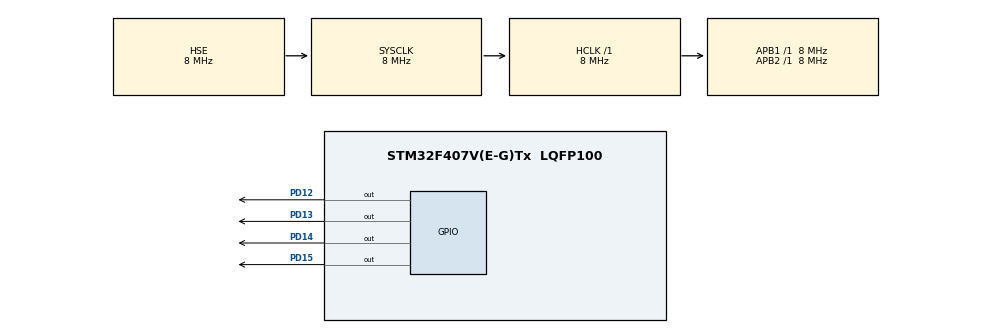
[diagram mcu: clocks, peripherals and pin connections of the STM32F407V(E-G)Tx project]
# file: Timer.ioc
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Mcu.Family=STM32F4
Mcu.Name=STM32F407V(E-G)Tx
Mcu.Package=LQFP100
NVIC.PriorityGroup=NVIC_PRIORITYGROUP_0
PA13.Mode=Serial_Wire
PA13.Signal=SYS_JTMS-SWDIO
PA14.Mode=Serial_Wire
PA14.Signal=SYS_JTCK-SWCLK
PD12.GPIO_PuPd=GPIO_PULLDOWN
PD12.Signal=GPIO_Output
PD13.GPIO_PuPd=GPIO_PULLDOWN
PD13.Signal=GPIO_Output
PD14.GPIO_PuPd=GPIO_PULLDOWN
PD14.Signal=GPIO_Output
PD15.GPIO_PuPd=GPIO_PULLDOWN
PD15.Signal=GPIO_Output
PH0-OSC_IN.Mode=HSE-External-Oscillator
PH0-OSC_IN.Signal=RCC_OSC_IN
PH1-OSC_OUT.Mode=HSE-External-Oscillator
PH1-OSC_OUT.Signal=RCC_OSC_OUT
ProjectManager.HeapSize=0x200
ProjectManager.StackSize=0x400
ProjectManager.TargetToolchain=STM32CubeIDE
RCC.48MHZClocksFreq_Value=13714285.714285715
RCC.AHBFreq_Value=8000000
RCC.APB1Freq_Value=8000000
RCC.APB1TimFreq_Value=8000000
RCC.APB2Freq_Value=8000000
RCC.APB2TimFreq_Value=8000000
RCC.CortexFreq_Value=8000000
RCC.HCLKFreq_Value=8000000
RCC.HSE_VALUE=8000000
RCC.HSI_VALUE=16000000
RCC.LSE_VALUE=32768
RCC.PLLQ=7
RCC.PLLSourceVirtual=RCC_PLLSOURCE_HSE
RCC.SYSCLKFreq_VALUE=8000000
RCC.SYSCLKSource=RCC_SYSCLKSOURCE_HSE
RCC.VCOOutputFreq_Value=96000000
TIM1.Period=1999
TIM1.Prescaler=7999
VP_TIM1_VS_ClockSourceINT.Mode=Internal
board=STM32F407G-DISC1

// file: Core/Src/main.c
/* USER CODE BEGIN Header */
/**
  ******************************************************************************
  * @file           : main.c
  * @brief          : Main program body
  ******************************************************************************
  * @attention
  *
  * Copyright (c) 2023 STMicroelectronics.
  * All rights reserved.
  *
  * This software is licensed under terms that can be found in the LICENSE file
  * in the root directory of this software component.
  * If no LICENSE file comes with this software, it is provided AS-IS.
  *
  ******************************************************************************
  */
/* USER CODE END Header */
#include "main.h"

TIM_HandleTypeDef htim1;

void SystemClock_Config(void);
static void MX_GPIO_Init(void);
static void MX_TIM1_Init(void);
/* USER CODE BEGIN PFP */
int state = 0;
/* USER CODE END PFP */

/* USER CODE BEGIN 0 */
HAL_TIM_PeriodElapsedCallback(TIM_HandleTypeDef *htim)
{
  state++ ;
  state = state % 2	;
  if(state == 0){
  HAL_GPIO_TogglePin(GPIOD, GPIO_PIN_12);
  HAL_GPIO_TogglePin(GPIOD, GPIO_PIN_13);
  HAL_GPIO_TogglePin(GPIOD, GPIO_PIN_14);
  HAL_GPIO_TogglePin(GPIOD, GPIO_PIN_15);
  }

}
/* USER CODE END 0 */

int main(void)
{

  /* MCU Configuration--------------------------------------------------------*/

  /* Reset of all peripherals, Initializes the Flash interface and the Systick. */
  HAL_Init();

  /* Configure the system clock */
  SystemClock_Config();

  /* Initialize all configured peripherals */
  MX_GPIO_Init();
  MX_TIM1_Init();
  /* USER CODE BEGIN 2 */
  HAL_TIM_Base_Start(&htim1);
  /* USER CODE END 2 */

  /* Infinite loop */
  while (1)
  {

    /* USER CODE BEGIN 3 */
	  if (__HAL_TIM_GET_FLAG(&htim1, TIM_FLAG_UPDATE)) // Timer tasmasi kontrolu
	     {
	       __HAL_TIM_CLEAR_FLAG(&htim1, TIM_FLAG_UPDATE); // Tasma bayragini temizle
	       // Timer taşması durumunda yapılacak işlemler
	       // Ornegin, bir LED'i yakabilirsiniz:
	       HAL_GPIO_TogglePin(GPIOD, GPIO_PIN_13);
	     }
  }
  /* USER CODE END 3 */
}

void SystemClock_Config(void)
{
  RCC_OscInitTypeDef RCC_OscInitStruct = {0};
  RCC_ClkInitTypeDef RCC_ClkInitStruct = {0};

  /** Configure the main internal regulator output voltage
  */
  __HAL_RCC_PWR_CLK_ENABLE();
  __HAL_PWR_VOLTAGESCALING_CONFIG(PWR_REGULATOR_VOLTAGE_SCALE1);

  /** Initializes the RCC Oscillators according to the specified parameters
  * in the RCC_OscInitTypeDef structure.
  */
  RCC_OscInitStruct.OscillatorType = RCC_OSCILLATORTYPE_HSE;
  RCC_OscInitStruct.HSEState = RCC_HSE_ON;
  RCC_OscInitStruct.PLL.PLLState = RCC_PLL_NONE;
  if (HAL_RCC_OscConfig(&RCC_OscInitStruct) != HAL_OK)
  {
    Error_Handler();
  }

  /** Initializes the CPU, AHB and APB buses clocks
  */
  RCC_ClkInitStruct.ClockType = RCC_CLOCKTYPE_HCLK|RCC_CLOCKTYPE_SYSCLK
                              |RCC_CLOCKTYPE_PCLK1|RCC_CLOCKTYPE_PCLK2;
  RCC_ClkInitStruct.SYSCLKSource = RCC_SYSCLKSOURCE_HSE;
  RCC_ClkInitStruct.AHBCLKDivider = RCC_SYSCLK_DIV1;
  RCC_ClkInitStruct.APB1CLKDivider = RCC_HCLK_DIV1;
  RCC_ClkInitStruct.APB2CLKDivider = RCC_HCLK_DIV1;

  if (HAL_RCC_ClockConfig(&RCC_ClkInitStruct, FLASH_LATENCY_0) != HAL_OK)
  {
    Error_Handler();
  }
}

static void MX_TIM1_Init(void)
{

  TIM_ClockConfigTypeDef sClockSourceConfig = {0};
  TIM_MasterConfigTypeDef sMasterConfig = {0};

  htim1.Instance = TIM1;
  htim1.Init.Prescaler = 7999;
  htim1.Init.CounterMode = TIM_COUNTERMODE_UP;
  htim1.Init.Period = 1999;
  htim1.Init.ClockDivision = TIM_CLOCKDIVISION_DIV1;
  htim1.Init.RepetitionCounter = 0;
  htim1.Init.AutoReloadPreload = TIM_AUTORELOAD_PRELOAD_DISABLE;
  if (HAL_TIM_Base_Init(&htim1) != HAL_OK)
  {
    Error_Handler();
  }
  sClockSourceConfig.ClockSource = TIM_CLOCKSOURCE_INTERNAL;
  if (HAL_TIM_ConfigClockSource(&htim1, &sClockSourceConfig) != HAL_OK)
  {
    Error_Handler();
  }
  sMasterConfig.MasterOutputTrigger = TIM_TRGO_RESET;
  sMasterConfig.MasterSlaveMode = TIM_MASTERSLAVEMODE_DISABLE;
  if (HAL_TIMEx_MasterConfigSynchronization(&htim1, &sMasterConfig) != HAL_OK)
  {
    Error_Handler();
  }

}

static void MX_GPIO_Init(void)
{
  GPIO_InitTypeDef GPIO_InitStruct = {0};

  /* GPIO Ports Clock Enable */
  __HAL_RCC_GPIOH_CLK_ENABLE();
  __HAL_RCC_GPIOD_CLK_ENABLE();
  __HAL_RCC_GPIOA_CLK_ENABLE();

  /*Configure GPIO pin Output Level */
  HAL_GPIO_WritePin(GPIOD, GPIO_PIN_12|GPIO_PIN_13|GPIO_PIN_14|GPIO_PIN_15, GPIO_PIN_RESET);

  /*Configure GPIO pins : PD12 PD13 PD14 PD15 */
  GPIO_InitStruct.Pin = GPIO_PIN_12|GPIO_PIN_13|GPIO_PIN_14|GPIO_PIN_15;
  GPIO_InitStruct.Mode = GPIO_MODE_OUTPUT_PP;
  GPIO_InitStruct.Pull = GPIO_PULLDOWN;
  GPIO_InitStruct.Speed = GPIO_SPEED_FREQ_LOW;
  HAL_GPIO_Init(GPIOD, &GPIO_InitStruct);

}

void Error_Handler(void)
{
  __disable_irq();
  while (1)
  {
  }
}
